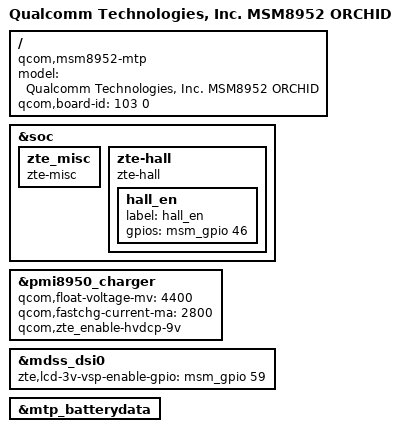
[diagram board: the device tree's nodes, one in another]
/*
 * Copyright (c) 2015, The Linux Foundation. All rights reserved.
 *
 * This program is free software; you can redistribute it and/or modify
 * it under the terms of the GNU General Public License version 2 and
 * only version 2 as published by the Free Software Foundation.
 *
 * This program is distributed in the hope that it will be useful,
 * but WITHOUT ANY WARRANTY; without even the implied warranty of
 * MERCHANTABILITY or FITNESS FOR A PARTICULAR PURPOSE.  See the
 * GNU General Public License for more details.
 */

/dts-v1/;

#include "msm8952-mtp.dtsi"
#include "zte-msm8952-orchid.dtsi"

/ {
	model = "Qualcomm Technologies, Inc. MSM8952 ORCHID";
	compatible = "qcom,msm8952-mtp", "qcom,msm8952", "qcom,mtp";
	qcom,board-id= <103 0>;
};
&soc {
        zte_misc {
                compatible = "zte-misc";
        };
        zte-hall {
                compatible = "zte-hall";
                hall_en{	                      
                        label = "hall_en";	
                        gpios = <&msm_gpio 46 0x0>;
            	};	
        };      
};
&pmi8950_charger {
	qcom,float-voltage-mv = <4400>;
	qcom,fastchg-current-ma = <2800>;
	qcom,zte_enable-hvdcp-9v;
};
&mdss_dsi0 {

	zte,lcd-3v-vsp-enable-gpio = <&msm_gpio 59 0>;
};
&mtp_batterydata {
	#include "ZTE_P852A01_4120mAh.dtsi"
};

